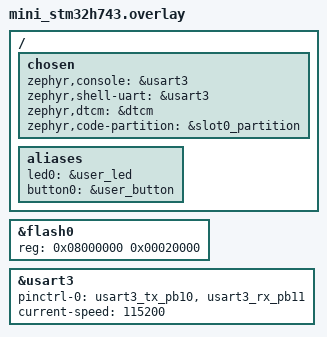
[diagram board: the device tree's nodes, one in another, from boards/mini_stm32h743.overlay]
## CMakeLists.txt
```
# SPDX-License-Identifier: Apache-2.0

cmake_minimum_required(VERSION 3.20.0)
set(FLASH_LOAD_OFFSET 0x90000000)
set(BOARD_ROOT "${CMAKE_CURRENT_LIST_DIR}/..")
find_package(Zephyr REQUIRED HINTS $ENV{ZEPHYR_BASE})
project(prj-learn)

# src/led.c src/button.c
target_sources(app PRIVATE src/led.c src/button.c)
```

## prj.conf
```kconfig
# Enable kernel heap for k_malloc/k_free
CONFIG_HEAP_MEM_POOL_SIZE=16384

# Stack size
CONFIG_MAIN_STACK_SIZE=4096

# 浮点数打印支持
CONFIG_CBPRINTF_FP_SUPPORT=y

# 外设
CONFIG_GPIO=y
CONFIG_SHELL=y

# 组件
CONFIG_ASSERT=y
CONFIG_PRINTK=y
CONFIG_CONSOLE=y
CONFIG_LOG=y
CONFIG_LOG_BUFFER_SIZE=2048

## Flash/NOR support (driver selected via devicetree)
CONFIG_FLASH=y
# CONFIG_SPI_NOR=y
```

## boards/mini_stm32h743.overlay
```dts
/ {
    chosen {
        zephyr,console = &usart3;
        zephyr,shell-uart = &usart3;
        zephyr,dtcm = &dtcm;
        zephyr,code-partition = &slot0_partition;
    };

    aliases {
        led0 = &user_led;
        button0 = &user_button;
    };
};

&flash0 {
    /* Set flash size to 128KB for STM32H750 */
    reg = <0x08000000 0x00020000>;
};

&usart3 {
	pinctrl-0 = <&usart3_tx_pb10 &usart3_rx_pb11>;
	pinctrl-names = "default";
	current-speed = <115200>;
	status = "okay";
};
```

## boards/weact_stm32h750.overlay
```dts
/* MCUBoot overlay for WeAct STM32H750 board
 * - Place MCUBoot in internal flash (128KB)
 * - Define external QSPI slots for Direct-XIP
 */

/ {
	/* For MCUBoot itself, link to internal flash */
	chosen {
		zephyr,console = &usart3;
        zephyr,shell-uart = &usart3;
		zephyr,flash = &flash0;
		zephyr,code-partition = &boot_partition;
	};
};

/* Internal Flash (128KB) holds MCUBoot */
&flash0 {
	partitions {
		compatible = "fixed-partitions";
		#address-cells = <1>;
		#size-cells = <1>;

		boot_partition: partition@0 {
			label = "mcuboot";
			reg = <0x00000000 0x00020000>; /* 128KB */
		};
	};
};
```

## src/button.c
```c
/*
 * Copyright (c) 2016 Open-RnD Sp. z o.o.
 * Copyright (c) 2020 Nordic Semiconductor ASA
 *
 * SPDX-License-Identifier: Apache-2.0
 *
 * NOTE: If you are looking into an implementation of button events with
 * debouncing, check out `input` subsystem and `samples/subsys/input/input_dump`
 * example instead.
 */

#include <zephyr/kernel.h>
#include <zephyr/device.h>
#include <zephyr/drivers/gpio.h>
#include <zephyr/sys/util.h>
#include <zephyr/sys/printk.h>
#include <inttypes.h>

#define SLEEP_TIME_MS 5

/*
 * Get button configuration from the devicetree button0 alias. This is mandatory.
 */
#define BUTTON0_NODE DT_ALIAS(button0)
#if !DT_NODE_HAS_STATUS_OKAY(BUTTON0_NODE)
#error "Unsupported board: button0 devicetree alias is not defined"
#endif
static const struct gpio_dt_spec button = GPIO_DT_SPEC_GET_OR(BUTTON0_NODE, gpios, {0});
static struct gpio_callback button_cb_data;

void button_pressed(const struct device *dev, struct gpio_callback *cb, uint32_t pins)
{
	printk("Button pressed at %" PRIu32 "\n", k_cycle_get_32());
}

int button_deal(void)
{
	int ret;

	if (!gpio_is_ready_dt(&button)) {
		printk("Error: button device %s is not ready\n", button.port->name);
		return 0;
	}

	ret = gpio_pin_configure_dt(&button, GPIO_INPUT);
	if (ret != 0) {
		printk("Error %d: failed to configure %s pin %d\n", ret, button.port->name,
		       button.pin);
		return 0;
	}

	ret = gpio_pin_interrupt_configure_dt(&button, GPIO_INT_EDGE_TO_ACTIVE);
	if (ret != 0) {
		printk("Error %d: failed to configure interrupt on %s pin %d\n", ret,
		       button.port->name, button.pin);
		return 0;
	}

	gpio_init_callback(&button_cb_data, button_pressed, BIT(button.pin));
	gpio_add_callback(button.port, &button_cb_data);
	printk("Set up button at %s pin %d\n", button.port->name, button.pin);

	printk("Press the button\n");

	while (1) {
		// int val = gpio_pin_get_dt(&button);

		// if (val >= 0) {
		// 	printk("button0 pressed %d", val);
		// }
		k_msleep(SLEEP_TIME_MS);
	}

	return 0;
}

K_THREAD_DEFINE(button_deal_id, 1024, button_deal, NULL, NULL, NULL, 5, 0, 0);
```
